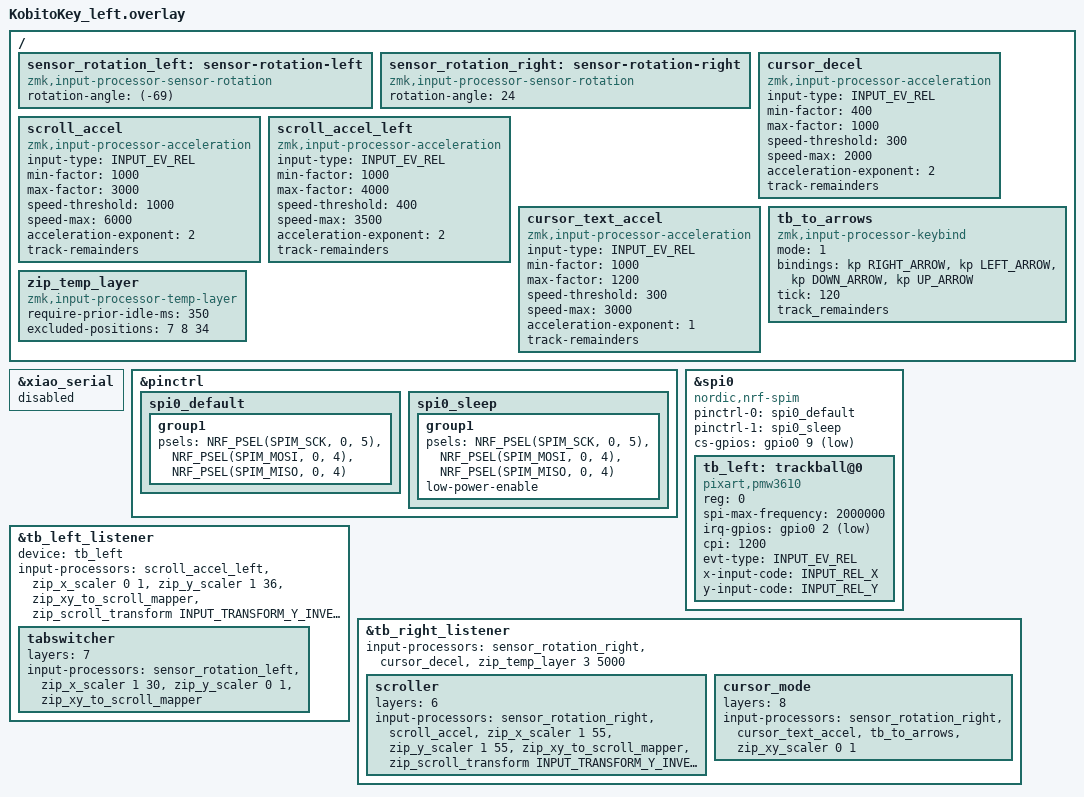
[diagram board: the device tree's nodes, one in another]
#include "kobitokey.dtsi"
#include <dt-bindings/zmk/keys.h>
#include <zephyr/dt-bindings/input/input-event-codes.h>
#include <input/processors.dtsi>
#include <input/processors/sensor_rotation.dtsi>

&xiao_serial { status = "disabled"; };

&pinctrl {
    spi0_default: spi0_default {
        group1 {
            psels = <NRF_PSEL(SPIM_SCK,  0, 5)>,
                    <NRF_PSEL(SPIM_MOSI, 0, 4)>,
                    <NRF_PSEL(SPIM_MISO, 0, 4)>;
        };
    };
    spi0_sleep: spi0_sleep {
        group1 {
            psels = <NRF_PSEL(SPIM_SCK,  0, 5)>,
                    <NRF_PSEL(SPIM_MOSI, 0, 4)>,
                    <NRF_PSEL(SPIM_MISO, 0, 4)>;
            low-power-enable;
        };
    };
};

&spi0 {
    status = "okay";
    compatible = "nordic,nrf-spim";
    pinctrl-0 = <&spi0_default>;
    pinctrl-1 = <&spi0_sleep>;
    pinctrl-names = "default", "sleep";
    cs-gpios = <&gpio0 9 GPIO_ACTIVE_LOW>;

    tb_left: trackball@0 {
        status = "okay";
        compatible = "pixart,pmw3610";
        reg = <0>;
        spi-max-frequency = <2000000>;
        irq-gpios = <&gpio0 2 (GPIO_ACTIVE_LOW | GPIO_PULL_UP)>;
        cpi = <1200>; /* センサー感度: 高解像度化により微小な回転も確実に検出 */


        evt-type = <INPUT_EV_REL>;
        x-input-code = <INPUT_REL_X>;
        y-input-code = <INPUT_REL_Y>;
    };
};

/ {
    sensor_rotation_left: sensor-rotation-left {
        compatible = "zmk,input-processor-sensor-rotation";
        status = "okay";
        #input-processor-cells = <0>;
        rotation-angle = <(-69)>; /* -24 から 45度回転を追加 */
    };

    sensor_rotation_right: sensor-rotation-right {
        compatible = "zmk,input-processor-sensor-rotation";
        #input-processor-cells = <0>;
        status = "okay";
        rotation-angle = <24>;
    };

    /* 右トラボのカーソル用 低速自動減速プロセッサ（19mmボールの精密操作対策）。
       高速側は max-factor=1000(等倍)のままにして、OS側のポインタ加速との
       二重加速（速い動きでの暴れ）を避け、低速時のみ自動でゲインを下げる。 */
    cursor_decel: cursor_decel {
        compatible = "zmk,input-processor-acceleration";
        #input-processor-cells = <0>;
        status = "okay";
        input-type = <INPUT_EV_REL>;
        min-factor = <400>;             /* 低速時の倍率(=0.4倍、精密モード相当) */
        max-factor = <1000>;            /* 高速時の倍率(=1.0倍、現状維持で加速なし) */
        speed-threshold = <300>;        /* この速度以下は精密固定(counts/sec) */
        speed-max = <2000>;             /* この速度で通常倍率(1.0倍)に到達 */
        acceleration-exponent = <2>;    /* 1=線形 2=二次 3=三次 */
        track-remainders;               /* 端数を持ち越して滑らかに */
    };

    /* 右トラボのスクロール用 加速プロセッサ（速く動かすほど倍率が上がる） */
    scroll_accel: scroll_accel {
        compatible = "zmk,input-processor-acceleration";
        #input-processor-cells = <0>;
        status = "okay";
        input-type = <INPUT_EV_REL>;
        min-factor = <1000>;            /* 低速時の倍率(=1.0倍、減速しない) */
        max-factor = <3000>;            /* 高速時の最大倍率(=3.0倍) */
        speed-threshold = <1000>;       /* これ以上の速度で加速開始(counts/sec) */
        speed-max = <6000>;             /* この速度で最大倍率に到達 */
        acceleration-exponent = <2>;    /* 1=線形 2=二次 3=三次 */
        track-remainders;               /* 端数を持ち越して滑らかに */
    };

    /* 左トラボのスクロール用 加速プロセッサ（右と独立管理）
       低速時は等倍(1.0倍)でゆっくり微細スクロールさせ、速く動かしたときは4.0倍まで急加速 */
    scroll_accel_left: scroll_accel_left {
        compatible = "zmk,input-processor-acceleration";
        #input-processor-cells = <0>;
        status = "okay";
        input-type = <INPUT_EV_REL>;
        min-factor = <1000>;            /* 低速時の倍率(=1.0倍、無駄な増幅を抑えて低速維持) */
        max-factor = <4000>;            /* 高速時の最大倍率(=4.0倍、素早く弾いた時に高速スクロール) */
        speed-threshold = <400>;        /* この速度から加速を開始(counts/sec) */
        speed-max = <3500>;             /* この速度で最大倍率に到達 */
        acceleration-exponent = <2>;    /* 1=線形 2=二次 3=三次 */
        track-remainders;               /* 端数を持ち越して滑らかに */
    };

    /* =========================================================================
     * 【新機能】テキストカーソル（矢印キー）用 移動プロセッサ
     *
     * 【設定3: 初動しきい値 / 速度暴走防止】
     * - min-factor: 初動・低速時の感度倍率（1000 = 等倍）。
     * - max-factor: 高速時の最大倍率。矢印キーが暴走連打されないよう 1200(1.2倍) に抑制。
     * - speed-threshold: この速度(counts/sec)からわずかに加速開始。
     * ========================================================================= */
    cursor_text_accel: cursor_text_accel {
        compatible = "zmk,input-processor-acceleration";
        #input-processor-cells = <0>;
        status = "okay";
        input-type = <INPUT_EV_REL>;
        min-factor = <1000>;            /* 初動・低速時の倍率(=1.0倍) */
        max-factor = <1200>;            /* 急速な連打を防ぐため最大1.2倍に抑制 */
        speed-threshold = <300>;        /* 加速開始の速度しきい値(counts/sec) */
        speed-max = <3000>;             /* 最大倍率に到達する速度 */
        acceleration-exponent = <1>;    /* 1=線形 2=二次 */
        track-remainders;               /* 端数を持ち越して滑らかに移動 */
    };

    /* トラックボールの移動量を矢印キー（↑ ↓ ← →）に変換するキーバインドプロセッサ */
    tb_to_arrows: tb_to_arrows {
        compatible = "zmk,input-processor-keybind";
        #input-processor-cells = <0>;
        mode = <1>; /* 4方向モード (1: 4-directional) */
        /* 方向順: 右, 左, 下, 上 */
        bindings = <&kp RIGHT_ARROW>, <&kp LEFT_ARROW>, <&kp DOWN_ARROW>, <&kp UP_ARROW>;
        tick = <120>; /* 【設定2: 感度】120カウント回すごとに矢印キーを1回発火（速度を大幅に落ち着かせる） */
        track_remainders; /* 端数を繰り越して微小回転も確実に拾う */
    };
};

&tb_left_listener {
    status = "okay";
    device = <&tb_left>;

    /* 回転(sensor_rotation_left)は外した。-69°回転だとスクロールが主に
       物理的な左右movementに反応してしまい「上下に動かすと逆・変」になるため。
       回転なし＝物理的な上下movementがそのまま縦スクロールになる。 */
    input-processors =
            <&scroll_accel_left>, /* 速く動かすほど速くスクロール（左用・独立設定） */
            <&zip_x_scaler 0 1>,  /* X(横)を無効化＝横スクロール出さない */
            <&zip_y_scaler 1 36>, /* Y(縦)を縦スクロールに使用。高解像度(CPI 1200)に合わせ除数を大きくし、たくさん回してゆっくりスクロール */
            <&zip_xy_to_scroll_mapper>,
            <&zip_scroll_transform INPUT_TRANSFORM_Y_INVERT>; /* 上下の向きを合わせる */

    /* tabswitchレイヤー(7)がアクティブな間だけ、左トラボの左右movementで
       水平スクロール(WheelLeft/WheelRight)を出す。PC側でCtrl+Tab等に変換して使う。 */
    tabswitcher {
        layers = <7>;
        input-processors =
            <&sensor_rotation_left>,
            <&zip_x_scaler 1 30>, /* 左右movement→水平スクロール */
            <&zip_y_scaler 0 1>,  /* 上下movementは無効化 */
            <&zip_xy_to_scroll_mapper>;
    };
};

/ {
  /omit-if-no-ref/ zip_temp_layer: zip_temp_layer {
    compatible = "zmk,input-processor-temp-layer";
    #input-processor-cells = <2>;
    require-prior-idle-ms = <350>; /* キー押下後、何msオートマウスレイヤに入らないようにするか、誤爆防止 */
  };
};

&tb_right_listener {
    status = "okay";

    input-processors =
        <&sensor_rotation_right>,
        <&cursor_decel>, /* 低速時のみ自動で精密モード(0.4倍)になり、高速時は通常通り(1.0倍) */
        <&zip_temp_layer 3 5000>; /* オートマウスレイヤーの指定とトラボ操作及びマウスボタン押下後に滞留する時間 */

    /* scrollレイヤー(6)がアクティブな間だけ、右トラボを縦スクロール動作にする。
       layerが一致するとprocess-next無しのためbaseプロセッサ(カーソル/オートマウス)はスキップされる。 */
    scroller {
        layers = <6>;
        input-processors =
            <&sensor_rotation_right>,
            <&scroll_accel>,          /* 速く動かすほど速くスクロール（加速） */
            <&zip_x_scaler 1 55>,     /* 横スクロール有効。CPI 1200に合わせ除数55でスクロール速度維持 */
            <&zip_y_scaler 1 55>,     /* 縦スクロール速度（同上） */
            <&zip_xy_to_scroll_mapper>,
            <&zip_scroll_transform INPUT_TRANSFORM_Y_INVERT>; /* スクロール方向を反転 */
    };

    /* =========================================================================
     * 【設定1: どちらのトラックボールを使うか】
     * 「右手トラックボール(&tb_right_listener)」にテキストカーソルモードを割り当てています。
     *
     * layer_8（レイヤー0でCキー押下中）がアクティブな間、
     * 右手トラックボールを矢印キー（テキスト入力カーソル移動）として動作させます。
     * ========================================================================= */
    cursor_mode {
        layers = <8>;
        input-processors =
            <&sensor_rotation_right>,  /* 右手トラボの物理回転補正 */
            <&cursor_text_accel>,      /* 【設定3】暴走抑制＆初動調整 */
            <&tb_to_arrows>,           /* 矢印キー（↑ ↓ ← →）を送出（感度はtb_to_arrowsのtickで設定） */
            <&zip_xy_scaler 0 1>;      /* マウスポインタ自体の移動をゼロ化（画面のマウスカーソルは動かさない） */
    };
};

&zip_temp_layer {
    excluded-positions = <
        7
        8
        34
    >;
};

/* マウスキー(&mkp)押下時のAMLタイムアウト延長設定は keymap 側
   (&mkp_input_listener)に定義。overlayはkeymapより先にパースされるため、
   behaviors.dtsi由来のノードをここで参照するとビルドエラーになる。 */
